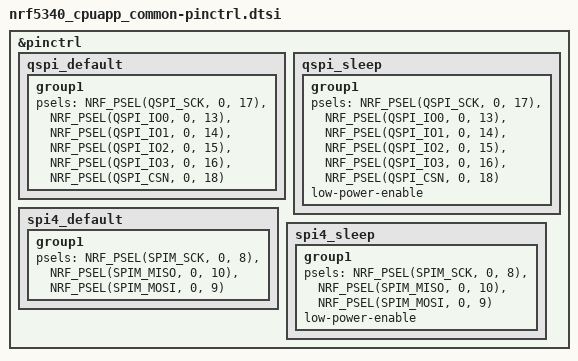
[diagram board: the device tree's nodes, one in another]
&pinctrl {

	qspi_default: qspi_default {
		group1 {
			psels = <NRF_PSEL(QSPI_SCK, 0, 17)>,
				<NRF_PSEL(QSPI_IO0, 0, 13)>,
				<NRF_PSEL(QSPI_IO1, 0, 14)>,
				<NRF_PSEL(QSPI_IO2, 0, 15)>,
				<NRF_PSEL(QSPI_IO3, 0, 16)>,
				<NRF_PSEL(QSPI_CSN, 0, 18)>;
		};
	};

	qspi_sleep: qspi_sleep {
		group1 {
			psels = <NRF_PSEL(QSPI_SCK, 0, 17)>,
				<NRF_PSEL(QSPI_IO0, 0, 13)>,
				<NRF_PSEL(QSPI_IO1, 0, 14)>,
				<NRF_PSEL(QSPI_IO2, 0, 15)>,
				<NRF_PSEL(QSPI_IO3, 0, 16)>,
				<NRF_PSEL(QSPI_CSN, 0, 18)>;
			low-power-enable;
		};
	};

	spi4_default: spi4_default {
		group1 {
			psels = <NRF_PSEL(SPIM_SCK, 0, 8)>,
			        <NRF_PSEL(SPIM_MISO, 0, 10)>,
			        <NRF_PSEL(SPIM_MOSI, 0, 9)>;
		};
	};

	spi4_sleep: spi4_sleep {
		group1 {
			psels = <NRF_PSEL(SPIM_SCK, 0, 8)>,
				<NRF_PSEL(SPIM_MISO, 0, 10)>,
				<NRF_PSEL(SPIM_MOSI, 0, 9)>;
			low-power-enable;
		};
	};
};

